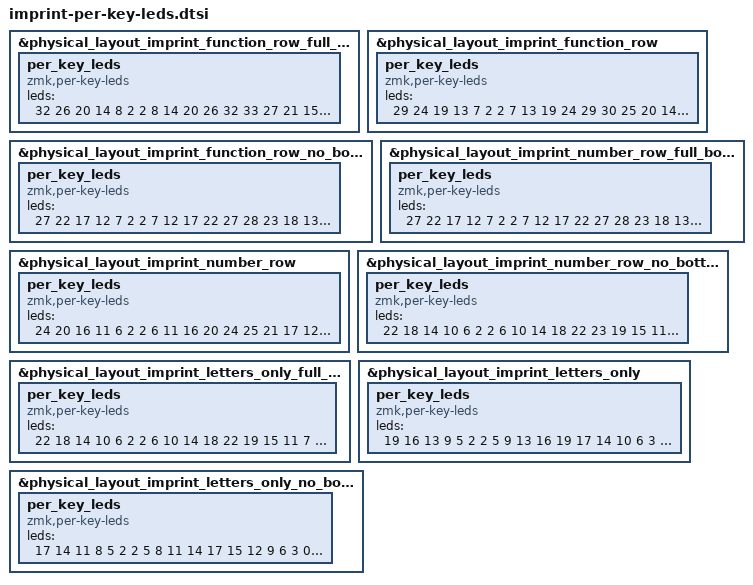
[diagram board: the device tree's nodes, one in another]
// GENERATED by scripts/gen_imprint_per_key_leds.py -- DO NOT EDIT BY HAND.
//
// Per-key RGB LED maps for the nine Imprint physical layouts, ported from QMK's
// rgb_matrix.layout (vial-qmk keyboards/cyboard/imprint/<cut>/info.json) so the
// wireless (ZMK) firmware can address each switch's own LED the way the wired
// (QMK) firmware already does. One source of truth; regenerate on QMK changes.
// See cyboard-wiki projects/studio-rgb-control.md (zmk-private#54, decision 2).
//
// Each map is a `per_key_leds` child of its zmk,physical-layout node, carrying
// `leds` indexed by key position (value = LED index on that key's own half's
// strip). A custom compatible keeps stock ZMK building (it ignores the unknown
// node) -- the same tactic as the status_indicators map (zmk-keyboards#31).
//
// Largest single-half strip across all cuts: 127 LEDs (flagship 5-key
// function-row). The shield's ws2812 chain-length must be >= that.

&physical_layout_imprint_function_row_full_bottom_row {
    per_key_leds {
        compatible = "zmk,per-key-leds";
        // key position -> LED index on that key's own half's strip
        // (82 keys; from QMK imprint_function_row_5key_bottom_row)
        leds = <
            32 26 20 14 8 2 2 8 14 20 26 32
            33 27 21 15 9 3 3 9 15 21 27 33
            34 28 22 16 10 4 4 10 16 22 28 34
            29 23 17 11 5 0 0 5 11 17 23 29
            30 24 18 12 6 1 1 6 12 18 24 30
            31 25 19 13 7 7 13 19 25 31 35 36
            37 37 36 35 38 39 40 40 39 38
        >;
    };
};

&physical_layout_imprint_function_row {
    per_key_leds {
        compatible = "zmk,per-key-leds";
        // key position -> LED index on that key's own half's strip
        // (76 keys; from QMK imprint_function_row_2key_bottom_row)
        leds = <
            29 24 19 13 7 2 2 7 13 19 24 29
            30 25 20 14 8 3 3 8 14 20 25 30
            31 26 21 15 9 4 4 9 15 21 26 31
            27 22 16 10 5 0 0 5 10 16 22 27
            28 23 17 11 6 1 1 6 11 17 23 28
            18 12 12 18 32 33 34 34 33 32 35 36
            37 37 36 35
        >;
    };
};

&physical_layout_imprint_function_row_no_bottom_row {
    per_key_leds {
        compatible = "zmk,per-key-leds";
        // key position -> LED index on that key's own half's strip
        // (72 keys; from QMK imprint_function_row_no_bottom_row)
        leds = <
            27 22 17 12 7 2 2 7 12 17 22 27
            28 23 18 13 8 3 3 8 13 18 23 28
            29 24 19 14 9 4 4 9 14 19 24 29
            25 20 15 10 5 0 0 5 10 15 20 25
            26 21 16 11 6 1 1 6 11 16 21 26
            30 31 32 32 31 30 33 34 35 35 34 33
        >;
    };
};

&physical_layout_imprint_number_row_full_bottom_row {
    per_key_leds {
        compatible = "zmk,per-key-leds";
        // key position -> LED index on that key's own half's strip
        // (70 keys; from QMK imprint_number_row_5key_bottom_row)
        leds = <
            27 22 17 12 7 2 2 7 12 17 22 27
            28 23 18 13 8 3 3 8 13 18 23 28
            24 19 14 9 4 0 0 4 9 14 19 24
            25 20 15 10 5 1 1 5 10 15 20 25
            26 21 16 11 6 6 11 16 21 26 29 30
            31 31 30 29 32 33 34 34 33 32
        >;
    };
};

&physical_layout_imprint_number_row {
    per_key_leds {
        compatible = "zmk,per-key-leds";
        // key position -> LED index on that key's own half's strip
        // (64 keys; from QMK imprint_number_row_2key_bottom_row)
        leds = <
            24 20 16 11 6 2 2 6 11 16 20 24
            25 21 17 12 7 3 3 7 12 17 21 25
            22 18 13 8 4 0 0 4 8 13 18 22
            23 19 14 9 5 1 1 5 9 14 19 23
            15 10 10 15 26 27 28 28 27 26 29 30
            31 31 30 29
        >;
    };
};

&physical_layout_imprint_number_row_no_bottom_row {
    per_key_leds {
        compatible = "zmk,per-key-leds";
        // key position -> LED index on that key's own half's strip
        // (60 keys; from QMK imprint_number_row_no_bottom_row)
        leds = <
            22 18 14 10 6 2 2 6 10 14 18 22
            23 19 15 11 7 3 3 7 11 15 19 23
            20 16 12 8 4 0 0 4 8 12 16 20
            21 17 13 9 5 1 1 5 9 13 17 21
            24 25 26 26 25 24 27 28 29 29 28 27
        >;
    };
};

&physical_layout_imprint_letters_only_full_bottom_row {
    per_key_leds {
        compatible = "zmk,per-key-leds";
        // key position -> LED index on that key's own half's strip
        // (58 keys; from QMK imprint_letters_only_5key_bottom_row)
        leds = <
            22 18 14 10 6 2 2 6 10 14 18 22
            19 15 11 7 3 0 0 3 7 11 15 19
            20 16 12 8 4 1 1 4 8 12 16 20
            21 17 13 9 5 5 9 13 17 21 23 24
            25 25 24 23 26 27 28 28 27 26
        >;
    };
};

&physical_layout_imprint_letters_only {
    per_key_leds {
        compatible = "zmk,per-key-leds";
        // key position -> LED index on that key's own half's strip
        // (52 keys; from QMK imprint_letters_only_2key_bottom_row)
        leds = <
            19 16 13 9 5 2 2 5 9 13 16 19
            17 14 10 6 3 0 0 3 6 10 14 17
            18 15 11 7 4 1 1 4 7 11 15 18
            12 8 8 12 20 21 22 22 21 20 23 24
            25 25 24 23
        >;
    };
};

&physical_layout_imprint_letters_only_no_bottom_row {
    per_key_leds {
        compatible = "zmk,per-key-leds";
        // key position -> LED index on that key's own half's strip
        // (48 keys; from QMK imprint_letters_only_no_bottom_row)
        leds = <
            17 14 11 8 5 2 2 5 8 11 14 17
            15 12 9 6 3 0 0 3 6 9 12 15
            16 13 10 7 4 1 1 4 7 10 13 16
            18 19 20 20 19 18 21 22 23 23 22 21
        >;
    };
};
